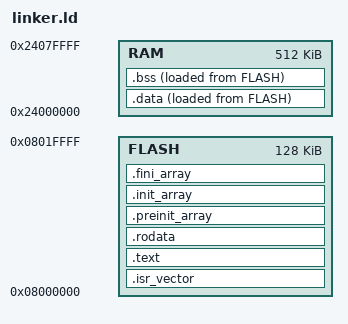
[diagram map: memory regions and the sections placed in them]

MEMORY
{
    FLASH : ORIGIN = 0x08000000, len = 128K
    RAM   : ORIGIN = 0x24000000, len = 512K
}

ENTRY(Reset_Handler)

_estack = ORIGIN(RAM) + LENGTH(RAM);

SECTIONS
{
    .isr_vector :
    {
        . = ALIGN(4);
        KEEP(*(.isr_vector))
        . = ALIGN(4);
    } > FLASH

    .text :
    {
        *(.text)
        *(.text*)
    } > FLASH

    .rodata :
    {
        *(.rodata)
        *(.rodata*)
    } > FLASH

    _sidata = LOADADDR(.data);

    .preinit_array (READONLY) : /* The READONLY keyword is only supported in GCC11 and later, remove it if using GCC10 or earlier. */
    {
      PROVIDE_HIDDEN (__preinit_array_start = .);
      KEEP (*(.preinit_array*))
      PROVIDE_HIDDEN (__preinit_array_end = .);
    } > FLASH
    .init_array (READONLY) : /* The READONLY keyword is only supported in GCC11 and later, remove it if using GCC10 or earlier. */
    {
      PROVIDE_HIDDEN (__init_array_start = .);
      KEEP (*(SORT(.init_array.*)))
      KEEP (*(.init_array*))
      PROVIDE_HIDDEN (__init_array_end = .);
    } >FLASH
    .fini_array (READONLY) : /* The READONLY keyword is only supported in GCC11 and later, remove it if using GCC10 or earlier. */
    {
      PROVIDE_HIDDEN (__fini_array_start = .);
      KEEP (*(SORT(.fini_array.*)))
      KEEP (*(.fini_array*))
      PROVIDE_HIDDEN (__fini_array_end = .);
    } >FLASH

    .data :
    {
        _sdata = .;
        *(.data)
        *(.data*)
        _edata = .;
    } > RAM AT > FLASH

    .bss :
    {
        _sbss = .;
        *(.bss)
        *(.bss*)
        _ebss = .;
    } > RAM AT > FLASH
}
